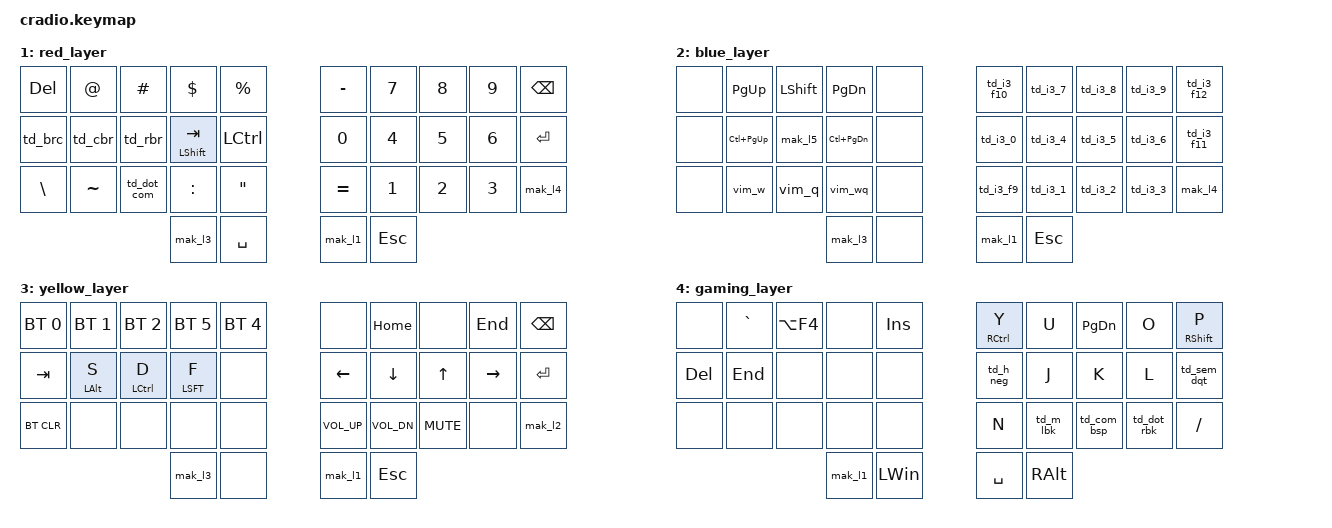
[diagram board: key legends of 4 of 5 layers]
// Copyright (c) 2022 The ZMK Contributors
// SPDX-License-Identifier: MIT

#include <behaviors.dtsi>
#include <dt-bindings/zmk/keys.h>
#include <dt-bindings/zmk/bt.h>

#define TAP_TERM_DEFAULT 200

// Home row mods macro
#define HRML(k1,k2,k3) &ht LALT k1  &ht LCTRL k2  &ht LSHFT k3
#define HRMR(k1,k2,k3) &ht RSHFT k1  &ht LCTRL k2  &ht RALT k3
#define L_GREEN 0
#define L_RED 1
#define L_BLUE 2
#define L_YELLOW 3
#define L_GAMING 4

// Makro creation
#define MACRO(name, keys)                 \
name: name##_macro {                      \
    label          = #name;               \
    compatible     = "zmk,behavior-macro";\
    tap-ms         = <1>;                 \
    wait-ms        = <1>;                 \
    #binding-cells = <0>;                 \
    bindings       = <keys>;              \
};

/ {
    behaviors {
        ht: hold_tap {
            compatible = "zmk,behavior-hold-tap";
            label = "HOMEROW_MODS";
            #binding-cells = <2>;
            tapping-term-ms = <200>;
            quick-tap-ms = <0>;
            flavor = "balanced";
            bindings = <&kp>, <&kp>;
        };
        td_b_gam_ret: behavior_tap_dance {
            compatible = "zmk,behavior-tap-dance";
            #binding-cells = <0>;
            bindings = <&lt L_BLUE RETURN>, <&lt L_GAMING RETURN>;
        };
        td_h_neg: tap_dance_h_neg {
            compatible = "zmk,behavior-tap-dance";
            label = "TAP_DANCE_H_NEG";
            #binding-cells = <0>;
            tapping-term-ms = <TAP_TERM_DEFAULT>;
            bindings = <&kp H>, <&kp MINUS>;
        };
        td_m_lbk: tap_dance_m_lbk {
            compatible = "zmk,behavior-tap-dance";
            label = "TAP_DANCE_M_LBK";
            #binding-cells = <0>;
            tapping-term-ms = <TAP_TERM_DEFAULT>;
            bindings = <&kp M>, <&kp LBKT>;
        };
        td_dot_rbk: tap_dance_dot_rbk {
            compatible = "zmk,behavior-tap-dance";
            label = "TAP_DANCE_DOT_RBK";
            #binding-cells = <0>;
            tapping-term-ms = <TAP_TERM_DEFAULT>;
            bindings = <&kp DOT>, <&kp RBKT>;
        };
        td_com_bsp: tap_dance_com_bsp {
            compatible = "zmk,behavior-tap-dance";
            label = "TAP_DANCE_COM_BSP";
            #binding-cells = <0>;
            tapping-term-ms = <TAP_TERM_DEFAULT>;
            bindings = <&kp COMMA>, <&kp BACKSPACE>;
        };
        td_sem_dqt: tap_dance_sem_dqt {
            compatible = "zmk,behavior-tap-dance";
            label = "TAP_DANCE_SEM_DQT";
            #binding-cells = <0>;
            tapping-term-ms = <TAP_TERM_DEFAULT>;
            bindings = <&kp SEMI>, <&kp SQT>;
        };
        td_com_tab: tap_dance_com_tab {
            compatible = "zmk,behavior-tap-dance";
            label = "TAP_DANCE_COM_TAB";
            #binding-cells = <0>;
            tapping-term-ms = <TAP_TERM_DEFAULT>;
            bindings = <&kp COMMA>, <&kp TAB>;
        };
        td_brc: tap_dance_brc {
            compatible = "zmk,behavior-tap-dance";
            label = "TAP_DANCE_BRC";
            #binding-cells = <0>;
            tapping-term-ms = <TAP_TERM_DEFAULT>;
            bindings = <&kp LBKT>, <&kp RBKT>;
        };
        td_cbr: tap_dance_cbr {
            compatible = "zmk,behavior-tap-dance";
            label = "TAP_DANCE_CBR";
            #binding-cells = <0>;
            tapping-term-ms = <TAP_TERM_DEFAULT>;
            bindings = <&kp LBRC>, <&kp RBRC>;
        };
        td_rbr: tap_dance_rbr {
            compatible = "zmk,behavior-tap-dance";
            label = "TAP_DANCE_RBR";
            #binding-cells = <0>;
            tapping-term-ms = <TAP_TERM_DEFAULT>;
            bindings = <&kp LPAR>, <&kp RPAR>;
        };
        td_dot_com: tap_dance_dot_com {
            compatible = "zmk,behavior-tap-dance";
            label = "TAP_DANCE_DOT_COM";
            #binding-cells = <0>;
            tapping-term-ms = <TAP_TERM_DEFAULT>;
            bindings = <&kp DOT>, <&kp COMMA>;
        };
        td_i3_0: tap_dance_i3_0 {
            compatible = "zmk,behavior-tap-dance";
            label = "TAP_DANCE_I3_0";
            #binding-cells = <0>;
            tapping-term-ms = <TAP_TERM_DEFAULT>;
            bindings = <&kp LA(N0)>, <&kp LA(LS(N0))>;
        };
        td_i3_1: tap_dance_i3_1 {
            compatible = "zmk,behavior-tap-dance";
            label = "TAP_DANCE_I3_1";
            #binding-cells = <0>;
            tapping-term-ms = <TAP_TERM_DEFAULT>;
            bindings = <&kp LA(N1)>, <&kp LA(LS(N1))>;
        };
        td_i3_2: tap_dance_i3_2 {
            compatible = "zmk,behavior-tap-dance";
            label = "TAP_DANCE_I3_2";
            #binding-cells = <0>;
            tapping-term-ms = <TAP_TERM_DEFAULT>;
            bindings = <&kp LA(N2)>, <&kp LA(LS(N2))>;
        };
        td_i3_3: tap_dance_i3_3 {
            compatible = "zmk,behavior-tap-dance";
            label = "TAP_DANCE_I3_3";
            #binding-cells = <0>;
            tapping-term-ms = <TAP_TERM_DEFAULT>;
            bindings = <&kp LA(N3)>, <&kp LA(LS(N3))>;
        };
        td_i3_4: tap_dance_i3_4 {
            compatible = "zmk,behavior-tap-dance";
            label = "TAP_DANCE_I3_4";
            #binding-cells = <0>;
            tapping-term-ms = <TAP_TERM_DEFAULT>;
            bindings = <&kp LA(N4)>, <&kp LA(LS(N4))>;
        };
        td_i3_5: tap_dance_i3_5 {
            compatible = "zmk,behavior-tap-dance";
            label = "TAP_DANCE_I3_5";
            #binding-cells = <0>;
            tapping-term-ms = <TAP_TERM_DEFAULT>;
            bindings = <&kp LA(N5)>, <&kp LA(LS(N5))>;
        };
        td_i3_6: tap_dance_i3_6 {
            compatible = "zmk,behavior-tap-dance";
            label = "TAP_DANCE_I3_6";
            #binding-cells = <0>;
            tapping-term-ms = <TAP_TERM_DEFAULT>;
            bindings = <&kp LA(N6)>, <&kp LA(LS(N6))>;
        };
        td_i3_7: tap_dance_i3_7 {
            compatible = "zmk,behavior-tap-dance";
            label = "TAP_DANCE_I3_7";
            #binding-cells = <0>;
            tapping-term-ms = <TAP_TERM_DEFAULT>;
            bindings = <&kp LA(N7)>, <&kp LA(LS(N7))>;
        };
        td_i3_8: tap_dance_i3_8 {
            compatible = "zmk,behavior-tap-dance";
            label = "TAP_DANCE_I3_8";
            #binding-cells = <0>;
            tapping-term-ms = <TAP_TERM_DEFAULT>;
            bindings = <&kp LA(N8)>, <&kp LA(LS(N8))>;
        };
        td_i3_9: tap_dance_i3_9 {
            compatible = "zmk,behavior-tap-dance";
            label = "TAP_DANCE_I3_9";
            #binding-cells = <0>;
            tapping-term-ms = <TAP_TERM_DEFAULT>;
            bindings = <&kp LA(N9)>, <&kp LA(LS(N9))>;
        };
        td_i3_f9: tap_dance_i3_f9 {
            compatible = "zmk,behavior-tap-dance";
            label = "TAP_DANCE_I3_F9";
            #binding-cells = <0>;
            tapping-term-ms = <TAP_TERM_DEFAULT>;
            bindings = <&kp LA(F9)>, <&kp LA(LS(F9))>;
        };
        td_i3_f10: tap_dance_i3_f10 {
            compatible = "zmk,behavior-tap-dance";
            label = "TAP_DANCE_I3_F10";
            #binding-cells = <0>;
            tapping-term-ms = <TAP_TERM_DEFAULT>;
            bindings = <&kp LA(F10)>, <&kp LA(LS(F10))>;
        };
        td_i3_f11: tap_dance_i3_f11 {
            compatible = "zmk,behavior-tap-dance";
            label = "TAP_DANCE_I3_F11";
            #binding-cells = <0>;
            tapping-term-ms = <TAP_TERM_DEFAULT>;
            bindings = <&kp LA(F11)>, <&kp LA(LS(F11))>;
        };
        td_i3_f12: tap_dance_i3_f12 {
            compatible = "zmk,behavior-tap-dance";
            label = "TAP_DANCE_I3_F12";
            #binding-cells = <0>;
            tapping-term-ms = <TAP_TERM_DEFAULT>;
            bindings = <&kp LA(F12)>, <&kp LA(LS(F12))>;
        };
        td_lsw_return: tap_dance_lsw_return {
            compatible = "zmk,behavior-tap-dance";
            label = "TAP_DANCE_LSW_RETURN";
            #binding-cells = <0>;
            tapping-term-ms = <TAP_TERM_DEFAULT>;
            bindings = <&kp RETURN>, <&mak_l2> ;
        };
        td_v_l3: tap_dance_v_l3 {
            compatible = "zmk,behavior-tap-dance";
            label = "TAP_DANCE_V_L3";
            #binding-cells = <0>;
            tapping-term-ms = <TAP_TERM_DEFAULT>;
            bindings = <&kp V>, <&mak_l3>;
        };
    };

    macros {
            MACRO(mak_l1, &to 0 &kp LC(LG(F1)))
            MACRO(mak_l2, &to 1 &kp LC(LG(F2)))
            MACRO(mak_l3, &to 2 &kp LC(LG(F3)))
            MACRO(mak_l4, &to 3 &kp LC(LG(F5)))
            MACRO(mak_l5, &to 4 &kp LC(LG(F6)))
            MACRO(vim_w, &kp ESCAPE &kp COLON &kp W &kp RETURN)
            MACRO(vim_wq, &kp ESCAPE &kp COLON &kp W &kp Q &kp RETURN)
            MACRO(vim_q, &kp ESCAPE &kp COLON &kp Q &kp EXCLAMATION &kp RETURN)
    };

    keymap {
        compatible = "zmk,keymap";

        green_layer {
            bindings = <
 //╭────────────────┬──────────┬─────────────┬───────────────┬─────────────────╮       ╭─────────────────┬──────────┬─────────────────┬──────────┬────────────────╮
 //│  Q GAMING      │  W       │    E        │   R           │  T              │       │  Y              │  U       │         I       │  O       │        P       │
     &lt L_GAMING Q   &kp W        &kp E        &kp R          &kp T                     &kp Y             &kp U      &kp I             &kp O      &kp P
 //├────────────────┼──────────┼─────────────┼───────────────┼─────────────────┤       ├─────────────────┼──────────┼─────────────────┼──────────┼────────────────┤
 //│  A             │  S       │    D        │   F           │  G              │       │  H              │  J       │         K       │  L       │       ' "      │
     &lt L_RED A      HRML(S,       D,           F)            &lt L_YELLOW G            &kp H             HRMR(J,          K,           L)        &td_sem_dqt
 //├────────────────┼──────────┼─────────────┼───────────────┼─────────────────┤       ├─────────────────┼──────────┼─────────────────┼──────────┼────────────────┤
 //│  Z             │  X       │    C        │   V           │  B              │       │  N              │  M       │        , <      │ . >      │       / ?      │
     &kp Z            &kp X      &kp C         &td_v_l3        &kp B                     &kp N             &kp M      &td_com_tab       &kp DOT    &kp FSLH
 //╰────────────────┴──────────┴─────────────┼───────────────┼─────────────────┤       ├─────────────────┼──────────┼─────────────────┴──────────┴────────────────╯
                                           &lt L_BLUE RETURN       &kp SPACE                 &td_lsw_return   &ht RGUI ESCAPE
 //                                      ╰───────────────────┴─────────────────╯       ╰─────────────────┴─────────────────────╯
     >;
 };

 red_layer {
     bindings = <
 //╭──────────┬───────────┬─────────────┬───────────────┬───────────╮         ╭───────────┬─────────────┬──────────┬──────────┬────────────╮
 //│ DELETE   │    @      │     #       │      $        │     %     │         │     -     │      7      │     8    │     9    │ BACKSPACE  │
     &kp DEL    &kp AT      &kp HASH      &kp DOLLAR      &kp PRCNT             &kp MINUS   &kp N7        &kp N8     &kp N9     &kp BSPC
 //├──────────┼───────────┼─────────────┼───────────────┼───────────┤         ├───────────┼─────────────┼──────────┼──────────┼────────────┤
 //│    []    │    {}     │    ()       │   SHIFT TAB   │   CTRL    │         │     0     │      4      │     5    │     6    │  RETURN    │
     &td_brc    &td_cbr     &td_rbr       &ht LSHFT TAB   &kp LCTRL             &kp N0      &kp N4        &kp N5     &kp N6     &kp RETURN
 //├──────────┼───────────┼─────────────┼───────────────┼───────────┤         ├───────────┼─────────────┼──────────┼──────────┼────────────┤
 //│     \    │     ~     │    ,.       │      :        │     "     │         │     =     │      1      │     2    │     3    │            │
     &kp BSLH   &kp TILDE   &td_dot_com   &kp COLON       &kp DQT               &kp EQUAL   &kp N1        &kp N2     &kp N3     &mak_l4
 //╰──────────┴───────────┴─────────────┼───────────────┼───────────┤         ├───────────┼─────────────┼──────────┴──────────┴────────────╯
                                           &mak_l3        &kp SPACE             &mak_l1      &kp ESCAPE
 //                                     ╰───────────────┴───────────╯         ╰───────────┴─────────────╯
     >;
 };

 blue_layer {
     bindings = <
 //╭───────────────┬───────────────┬───────────┬───────────────┬──────────────╮   ╭────────────┬─────────────┬─────────────┬─────────────┬────────────╮
 //│               │ SCROLL UP     │   SHIFT   │ SCROLL DN     │              │   │            │             │             │             │            │
     &none           &kp PG_UP       &kp LSHFT   &kp PG_DN       &none              &td_i3_f10   &td_i3_7      &td_i3_8      &td_i3_9      &td_i3_f12
 //├───────────────┼───────────────┼───────────┼───────────────┼──────────────┤   ├────────────┼─────────────┼─────────────┼─────────────┼────────────┤
 //│               │  NXTTAB       │ GAM LAYR  │   PRVTAB      │              │   │            │             │             │             │            │
     &none           &kp LC(PG_UP)   &mak_l5     &kp LC(PG_DN)   &none              &td_i3_0     &td_i3_4      &td_i3_5      &td_i3_6      &td_i3_f11
 //├───────────────┼───────────────┼───────────┼───────────────┼──────────────┤   ├────────────┼─────────────┼─────────────┼─────────────┼────────────┤
 //│               │               │           │               │              │   │            │             │             │             │            │
     &none           &vim_w          &vim_q       &vim_wq        &none            &td_i3_f9    &td_i3_1      &td_i3_2      &td_i3_3      &mak_l4
 //╰───────────────┴───────────────┴───────────┼───────────────┼──────────────┤   ├────────────┼─────────────┼─────────────┴─────────────┴────────────╯
                                                          &mak_l3     &none         &mak_l1     &kp ESCAPE
 //                                                     ╰──────────┴──────────╯   ╰──────────┴───────────────╯
     >;
 };

 yellow_layer {
     bindings = <
 //╭──────────────┬──────────────┬──────────────┬──────────────┬──────────────╮   ╭──────────────┬───────────────┬────────────┬───────────┬───────────╮
 //│ BT PROFILE 1 │ BT PROFILE 2 │ BT PROFILE 3 │ BT PROFILE 4   BT PROFILE 5 │   │              │   HOME        │            │   END     │   BSPC    │
     &bt BT_SEL 0   &bt BT_SEL 1   &bt BT_SEL 2   &bt BT_SEL 5   &bt BT_SEL 4       &none          &kp HOME        &none        &kp END     &kp BSPC
 //├──────────────┼──────────────┼──────────────┼──────────────┼──────────────┤   ├──────────────┼───────────────┼────────────┼───────────┼───────────┤
 //│   TAB        │   LALT S     │    LCTRL D   │    LSFT F    │              │   │   LEFT       │   DOWN        │    UP      │   RIGHT   │   RETURN  │
     &kp TAB        &ht LALT S     &ht LCTRL D    &ht LSFT F     &none              &kp LEFT       &kp DOWN        &kp UP       &kp RIGHT  &kp RETURN
 //├──────────────┼──────────────┼──────────────┼──────────────┼──────────────┤   ├──────────────┼───────────────┼────────────┼───────────┼───────────┤
 //│ CLEAR BT     │              │              │              │                  │   VOL UP     │   VOL DN      │    MUTE    │           │  LAYER 2  │
     &bt BT_CLR     &none          &none          &none          &none              &kp C_VOL_UP   &kp C_VOL_DN    &kp C_MUTE   &none       &mak_l2
 //╰──────────────┴──────────────┴──────────────┼──────────────┼──────────────┤   ├──────────────┼───────────────┼────────────┴───────────┴───────────╯
                                                  &mak_l3        &none              &mak_l1        &kp ESCAPE                 
 //                                             ╰── ───────────┴────    ──────╯   ╰──────────────┴───────────────╯          ──
            >;
        };

        gaming_layer {
            bindings = <
        //╭────────────┬───────────┬─────────────┬──────────────┬──────────╮       ╭──────────────┬──────────────┬─────────────────┬────────────────┬────────────────╮
        //│  ?         │  `        │  ALT + F4   │   ?          │  INS     │       │  Y           │  U           │         I       │  O             │        P       │
            &none        &kp GRAVE   &kp LA(F4)    &none          &kp INS            &ht RCTRL Y    &kp U          &kp PG_DN         &kp O            &ht RSHFT P
        //├────────────┼───────────┼─────────────┼──────────────┼──────────┤       ├──────────────┼──────────────┼─────────────────┼────────────────┼────────────────┤
        //│  DEL       │  END      │    ?        │   ?          │  ?       │       │  H           │  J           │         K       │  L             │       ' "      │
            &kp DEL      &kp END      &none        &none          &none              &td_h_neg      &kp J          &kp K             &kp L            &td_sem_dqt
        //├────────────┼───────────┼─────────────┼──────────────┼──────────┤       ├──────────────┼──────────────┼─────────────────┼────────────────┼────────────────┤
        //│  ?         │  ?        │    ?        │   ?          │  ?       │       │  N           │  M           │        , <      │ . >            │       / ?      │
            &none        &none       &none         &none          &none              &kp N          &td_m_lbk      &td_com_bsp       &td_dot_rbk      &kp FSLH
        //╰────────────┴───────────┴─────────────┼──────────────┼──────────┤       ├──────────────┼──────────────┼─────────────────┴────────────────┴────────────────╯
                                                      &mak_l1     &kp LWIN           &kp SPACE      &kp RALT
        //                                           ╰──────────┴──────────╯       ╰──────────────┴──────────────╯
        // need: - (attack room), [ (enemys), ] (need weapon)
        // done: ` (console), ins (shad.cfg), del (ready), end (unready), backspace (smiley), ' (status),
            >;
        };
    };
};
